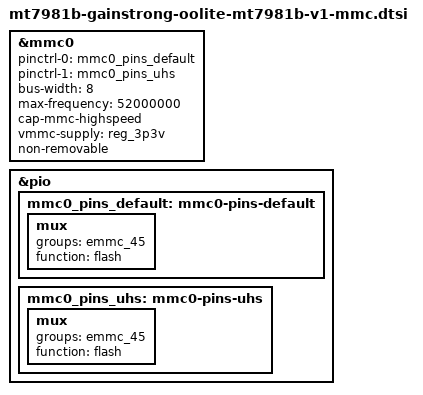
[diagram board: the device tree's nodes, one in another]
&mmc0 {
	pinctrl-names = "default", "state_uhs";
	pinctrl-0 = <&mmc0_pins_default>;
	pinctrl-1 = <&mmc0_pins_uhs>;
	bus-width = <8>;
	max-frequency = <52000000>;
	cap-mmc-highspeed;
	vmmc-supply = <&reg_3p3v>;
	non-removable;
	status = "okay";
};

&pio {
	mmc0_pins_default: mmc0-pins-default {
		mux {
			groups = "emmc_45";
			function = "flash";
		};
	};

	mmc0_pins_uhs: mmc0-pins-uhs {
		mux {
			groups = "emmc_45";
			function = "flash";
		};
	};
};
